# RS1xxxx register map
Vendor: Silicon Lab Inc.; Series: ARMCM4; File version: 1.2
CPU: CM4 r1p0, little endian, MPU, FPU, 6 interrupt priority bits
Registers are 32-bit, read-write, reset 0x0 unless marked. A register's access mark holds for its fields unless they carry their own. Offsets are from the block's base; [hi:lo] are bit positions; {n}, {i} and the like mark numbered series; 'fields as' and 'values as' point back to an identical list.

## QSPI_2 (part 2 of 2) — The queued serial peripheral interface module provides a serial peripheral interface with queued transfer capability
Base 0x12040000
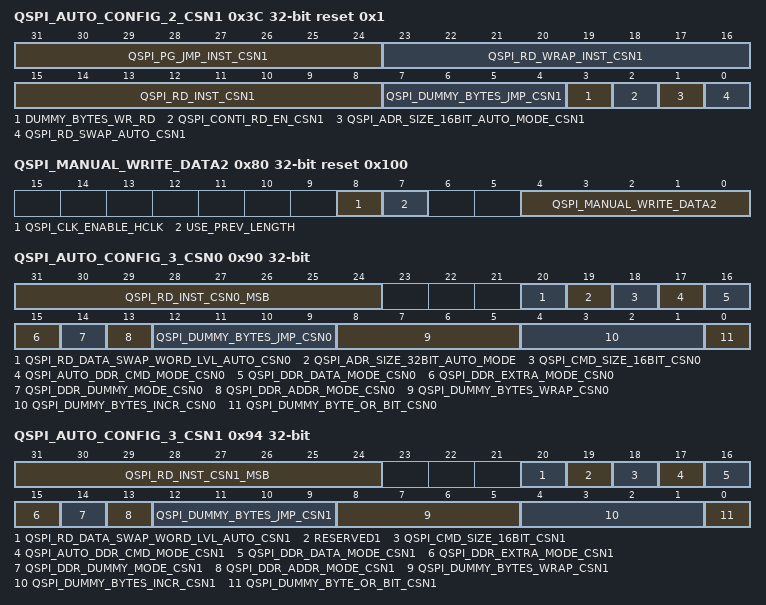
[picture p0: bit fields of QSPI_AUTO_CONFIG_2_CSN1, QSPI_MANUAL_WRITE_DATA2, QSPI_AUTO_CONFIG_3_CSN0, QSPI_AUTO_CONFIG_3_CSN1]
0x3C QSPI_AUTO_CONFIG_2_CSN1 reset 0x1 — QSPI Auto Controller Configuration 2 CSN1 Register
  [31:24] QSPI_PG_JMP_INST_CSN1 — Read instruction to be used, when Page jump is to be used.
  [23:16] QSPI_RD_WRAP_INST_CSN1 — Read instruction to be used for the selected SPI modes and when wrap is not needed or supported
  [15:8] QSPI_RD_INST_CSN1 — Read instruction to be used for the selected SPI modes and when wrap is not needed or supported
  [7:4] QSPI_DUMMY_BYTES_JMP_CSN1 — Dummy cycles to be selected in case of JUMP
  [3] DUMMY_BYTES_WR_RD — Dummy bytes to the model to be read or to be write.
    0=Disable (Dummy bytes will be read); 1=Enable (Dummy bytes to be write)
  [2] QSPI_CONTI_RD_EN_CSN1 — Continuous read enable bit.
    0=Disable (Continuous read disabled); 1=Enable (Continuous read enabled.)
  [1] QSPI_ADR_SIZE_16BIT_AUTO_MODE_CSN1 — Bit address sent to model
    0=Disable (24 Bit address is sent to model.); 1=Enable (16 Bit address is sent to model)
  [0] QSPI_RD_SWAP_AUTO_CSN1 — Swap the read data from the flash in byte order for chip select1 csn1 in auto mode.
    0=Swap_Disable (Swap is disabled.); 1=Swap_Enable (Swap is enabled)
0x80 QSPI_MANUAL_WRITE_DATA2 reset 0x100 (reset mask 0xFF)
  [8] QSPI_CLK_ENABLE_HCLK — Static clock enable for qspi hclock
  [7] USE_PREV_LENGTH — Use previous length.
    0=Disable (No action); 1=Enable (Uses previously programmed length in [4:0] of this register for next writes)
  [4:0] QSPI_MANUAL_WRITE_DATA2 — Number of bits to be written in write mode
0x90 QSPI_AUTO_CONFIG_3_CSN0 — QSPI Auto Controller Configuration 3 CSN0 Register
  [31:24] QSPI_RD_INST_CSN0_MSB — Read instruction MS byte to be used the selected SPI modes and when wrap is not needed or supported.
  [20] QSPI_RD_DATA_SWAP_WORD_LVL_AUTO_CSN0 — Rd data swap at word level in auto mode for csn0. It is valid for octa mode.
  [19] QSPI_ADR_SIZE_32BIT_AUTO_MODE — 32 bit addressing support enable.
    0=Disable (24/16 Bit address is sent to model.); 1=Enable (32 Bit address is sent to model.)
  [18] QSPI_CMD_SIZE_16BIT_CSN0 — Enable for 16 read cmd size for csn0.
    0=Disable (8 bit read command); 1=Enable (16 bit read command)
  [17] QSPI_AUTO_DDR_CMD_MODE_CSN0 — DDR data mode.In the SPI operation (cmd, addr, extra, dummy, data)
    0=Disable (Command byte is driven in SDR fashion.); 1=Enable (Command byte is driven in DDR fashion.)
  [16] QSPI_DDR_DATA_MODE_CSN0 — DDR data mode.In the SPI operation (cmd, addr, extra, dummy, data)
    0=Disable (Data are sampled in SDR fashion); 1=Enable (Data are sampled in DDR fashion)
  [15] QSPI_DDR_EXTRA_MODE_CSN0 — DDR extra byte mode.In the SPI operation (cmd, addr, extra, dummy, data)
    0=Disable (Dummy bytes are driven in SDR fashion.); 1=Enable (Dummy bytes are driven in DDR fashion.)
  [14] QSPI_DDR_DUMMY_MODE_CSN0 — DDR dummy byte mode.In the SPI operation (cmd, addr, extra, dummy, data)
    0=Disable (Extra byte is driven in SDR fashion.); 1=Enable (Extra byte is driven in DDR fashion.)
  [13] QSPI_DDR_ADDR_MODE_CSN0 — DDR Address mode. In the SPI operation (cmd, addr, extra, dummy, data)
    0=Disable (Address bytes are driven in SDR fashion); 1=Enable (Address bytes are driven in DDR fashion)
  [12:9] QSPI_DUMMY_BYTES_JMP_CSN0 — Dummy cycles to be selected in case of JUMP. It contains MS nibble of byte.
  [8:5] QSPI_DUMMY_BYTES_WRAP_CSN0 — Specifies the number of dummy bytes for the selected SPI mode in case of wrap instruction. It contains MS nibble for byte.
  [4:1] QSPI_DUMMY_BYTES_INCR_CSN0 — Specifies the number of dummy bytes for the selected SPI mode. It contains MS nibble for byte.
  [0] QSPI_DUMMY_BYTE_OR_BIT_CSN0 — Indicates all above mention values are dummy bytes or bits in auto mode.
    0=Disable (dummy bytes mode); 1=Enable (dummy bits mode)
0x94 QSPI_AUTO_CONFIG_3_CSN1 — QSPI Auto Controller Configuration 3 CSN1 Register
  [31:24] QSPI_RD_INST_CSN1_MSB — Read instruction MS byte to be used the selected SPI modes and when wrap is not needed or supported.
  [20] QSPI_RD_DATA_SWAP_WORD_LVL_AUTO_CSN1 — Rd data swap at word level in auto mode for csn1. It is valid for octa mode.
  [19] RESERVED1 — Reseerved1
  [18] QSPI_CMD_SIZE_16BIT_CSN1 — Enable for 16 read cmd size for csn1.
    values as QSPI_AUTO_CONFIG_3_CSN0.QSPI_CMD_SIZE_16BIT_CSN0
  [17] QSPI_AUTO_DDR_CMD_MODE_CSN1 — DDR data mode for csn1.In the SPI operation (cmd, addr, extra, dummy, data)
    0=Disable (Command byte is driven in SDR fashion); 2=Enable (Command byte is driven in DDR fashion)
  [16] QSPI_DDR_DATA_MODE_CSN1 — DDR data mode for csn1.In the SPI operation (cmd, addr, extra, dummy, data)
    0=Disable (Data are sampled in SDR fashion); 3=Enable (Data are sampled in DDR fashion)
  [15] QSPI_DDR_EXTRA_MODE_CSN1 — DDR extra byte mode for csn1.In the SPI operation (cmd, addr, extra, dummy, data)
    0=Disable (Dummy bytes are driven in SDR fashion); 4=Enable (Dummy bytes are driven in DDR fashion)
  [14] QSPI_DDR_DUMMY_MODE_CSN1 — DDR dummy byte mode for csn1.In the SPI operation (cmd, addr, extra, dummy, data)
    0=Disable (Extra byte is driven in SDR fashion); 5=Enable (Extra byte is driven in DDR fashion)
  [13] QSPI_DDR_ADDR_MODE_CSN1 — DDR address mode for csn1.In the SPI operation (cmd, addr, extra, dummy, data)
    0=Disable (Address bytes are driven in SDR fashion); 6=Enable (Address bytes are driven in DDR fashion)
  [12:9] QSPI_DUMMY_BYTES_JMP_CSN1 — Dummy cycles to be selected in case of JUMP. It contains MS nibble of byte.
  [8:5] QSPI_DUMMY_BYTES_WRAP_CSN1 — Specifies the number of dummy bytes for the selected SPI mode in case of wrap instruction. It contains MS nibble for byte.
  [4:1] QSPI_DUMMY_BYTES_INCR_CSN1 — Specifies the number of dummy bytes for the selected SPI mode. It contains MS nibble for byte.
  [0] QSPI_DUMMY_BYTE_OR_BIT_CSN1 — Indicates all above mention values are dummy bytes or bits in auto mode.
0xA0 QSPI_AUTO_BASE_ADDR_CSN0 — QSPI Controller auto Base address configuration CSN0 Register
  [31:0] QSPI_AUTO_BASE_ADDR_CSN0 — Holds the 32 bit base address for select chip select0 in programmable auto csn mode.It is valid only programmable auto csn mode is enabled.
0xA4 QSPI_AUTO_BASE_ADDR_CSN1 — QSPI Controller auto Base address configuration CSN1 Register
  [31:0] QSPI_AUTO_BASE_ADDR_CSN1 — Holds the 32 bit base address for select chip select1 in programmable auto csn mode.It is valid only programmable auto csn mode is enabled.
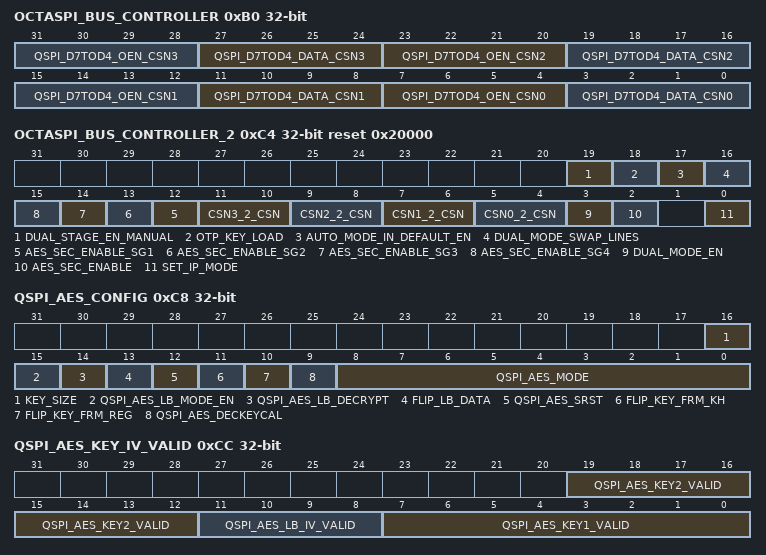
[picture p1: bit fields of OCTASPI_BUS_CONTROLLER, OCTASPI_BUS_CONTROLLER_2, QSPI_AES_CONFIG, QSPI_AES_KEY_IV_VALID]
0xB0 OCTASPI_BUS_CONTROLLER
  [8n+7:8n+4] QSPI_D7TOD4_OEN_CSN{n} (n=0..3) — Direction Control for SPI_IO 7,6,5 and 4 in case of quad/dual/single mode for chip select{n} (cs_n{n}). It is used both in Auto and Manual Mode.
  [27:24] QSPI_D7TOD4_DATA_CSN3 — Value of SPI_IO7,6,5 and 4 in case of quad/dual/single mode for chip select3 (cs_n3). It is used both in Auto and Manual Mode.
  [19:16] QSPI_D7TOD4_DATA_CSN2 — Value of SPI_IO7,6,5 and 4 in case of quad/dual/single mode for chip select2 (cs_n2). It is used both in Auto and Manual Mode.
  [11:8] QSPI_D7TOD4_DATA_CSN1 — Value of SPI_IO7,6,5 and 4 in case of quad/dual/single mode for chip select1 (cs_n1). It is used both in Auto and Manual Mode.
  [3:0] QSPI_D7TOD4_DATA_CSN0 — Value of SPI_IO7,6,5 and 4 in case of quad/dual/single mode for chip select1 (cs_n0). It is used both in Auto and Manual Mode.
0xB4 QSPI_AUTO_BASE_ADDR_UNMASK_CSN0 reset 0xFFFFFFFF — QSPI in Auto Base address mode for unmasking CSN0 Register
  [31:0] QSPI_AUTO_BASE_ADDR_UNMASK_CSN0 — Holds the 32 bit base address unmask value for select chip select0 in programmable auto csn mode. It is valid only programmable auto csn mode is enabled.
0xB8 QSPI_AUTO_BASE_ADDR_UNMASK_CSN1 reset 0xFFFFFFFF — QSPI in Auto Base address mode for unmasking CSN1 Register
  [31:0] QSPI_AUTO_BASE_ADDR_UNMASK_CSN1 — Holds the 32 bit base address unmask value for select chip select1 in programmable auto csn mode. It is valid only programmable auto csn mode is enabled.
0xC4 OCTASPI_BUS_CONTROLLER_2 reset 0x20000 — QSPI Controller2 in OCTA SPI Mode.
  [19] DUAL_STAGE_EN_MANUAL — Dual stage en for dual flash mode. It is valid only if dual_mode_en is set to high. This bit be one, while sending command, address, dummy bytes, and etc. It sends same command & address to both flashes. It should be zero while reading or writing data into flash in dual quad flash mode.
  [18] OTP_KEY_LOAD — Enable to load key from OTP/KH
  [17] AUTO_MODE_IN_DEFAULT_EN — Qspi works in auto mode if set this is bit by default.
  [16] DUAL_MODE_SWAP_LINES — This bit controls the 8 lines of qspi with 4 bit swap manner. If this is set, upper 4 lines are swapped with lower 4 lines.
  [n+11] AES_SEC_ENABLE_SG{n} (n=1..4) — This bit enables the AES security enable or not for segment {n}
  [11:10] CSN3_2_CSN — Map csn3 to the programmed csn. It is valid for both manual and auto modes
    0=CSN3_TO_CSN0 (Map csn3 to csn0. Reads on csn3 will have data from csn0 also.); 7=CSN3_TO_CSN1 (Map csn3 to csn1. Reads on csn3 will have data from csn0 also); 8=CSN3_TO_CSN2 (Map csn3 to csn2. Reads on csn3 will have data from csn0 also.); 3=NOT_VALID
  [9:8] CSN2_2_CSN — Map csn2 to the programmed csn. It is valid for both manual and auto modes
    0=CSN2_TO_CSN1 (Map csn2 to csn1. Reads on csn2 will have data from csn0 also); 9=CSN2_TO_CSN1 (Map csn2 to csn1. Reads on csn2 will have data from csn1 also); 10=NOT_VALID; 3=CSN2_TO_CSN3 (Map csn2 to csn3. Reads on csn2 will have data from csn3 also.)
  [7:6] CSN1_2_CSN — Map csn1 to the programmed csn. It is valid for both manual and auto modes
    0=CSN1_TO_CSN0 (Map csn1 to csn0. Reads on csn1 will have data from csn1 also); 11=NOT_VALID; 12=CSN1_TO_CSN2 (Map csn1 to csn2. Reads on csn1 will have data from csn2 also); 3=CSN1_TO_CSN3 (Map csn1 to csn3. Reads on csn1 will have data from csn3 also)
  [5:4] CSN0_2_CSN — Map csn0 to the programmed csn. It is valid for both manual and auto modes
    0=NOT_VALID; 13=CSN0_TO_CSN1 (Map csn0 to csn1. Reads on csn0 will have data from csn1 also); 14=CSN0_TO_CSN2 (Map csn0 to csn2. Reads on csn0 will have data from csn2 also); 3=CSN0_TO_CSN3 (Map csn0 to csn3. Reads on csn0 will have data from csn3 also)
  [3] DUAL_MODE_EN — Dual flash mode enable control. If two csns are cmnnected with the same kind of flash, QSPI can read data (4bit data each flash) from both the flashes at the same point of time (Not in TDM fashion). If set, both the flashes are accessed at the same point time, otherwise normal operation.
  [2] AES_SEC_ENABLE — This bit enables the AES security enable or not
  [0] SET_IP_MODE — This bit enables the qspi interface pins into HiZ mode
0xC8 QSPI_AES_CONFIG — QSPI Controller AES Mode, Key Size and Context switching
  [16] KEY_SIZE — QSPI key size
    0=Disable (124 bit key); 1=Enable (256 bit key)
  [15] QSPI_AES_LB_MODE_EN — QSPI AES LB mode (Standalone mode ) enable.
    0=Disable (Inline mode); 1=Enable (Standalone mode)
  [14] QSPI_AES_LB_DECRYPT — QSPI standalone mode
    0=Disable (Enables encryption mode in standalone mode); 1=Enables decryption mode in standalone mode
  [13] FLIP_LB_DATA — writing 1 to this Flips the 32-bit endian for data in standalone mode
  [12] QSPI_AES_SRST wo — Synchronous soft reset for AES Module. Write only bit. Reading this bit gives alway 0
  [11] FLIP_KEY_FRM_KH — writing 1 to this Flips the 32-bit endian key taken from kh
  [10] FLIP_KEY_FRM_REG — writing 1 to this Flips the 32-bit endian key taken from kh
  [9] QSPI_AES_DECKEYCAL — Enables pre-calculation of KEY before decryption operation. Set 1 fot XTS and 0 for CTR In encryption operations, it is 0. 1 not supported.
    0=Disable (use the input key for decryption operations.); 1=Enable (the pre-calculation of the key (K’=KeyExp(K)) is done before starting any data decryption operation)
  [8:0] QSPI_AES_MODE — AES mode of decryption CTR/XTS 0x80 - XTS 0x04 - CTR others not supported
0xCC QSPI_AES_KEY_IV_VALID — QSPI Controller AES write Enables for Keys and IVs
  [19:12] QSPI_AES_KEY2_VALID — Write enables for AES KEY 2. Denotes which bytes of key2 is valid
  [11:8] QSPI_AES_LB_IV_VALID — Write enables for AES IV1 in standalone mode. Denotes which bytes of IV1 is valid.
  [7:0] QSPI_AES_KEY1_VALID — Write enables for AES KEY 1. Denotes which bytes of key1 is valid
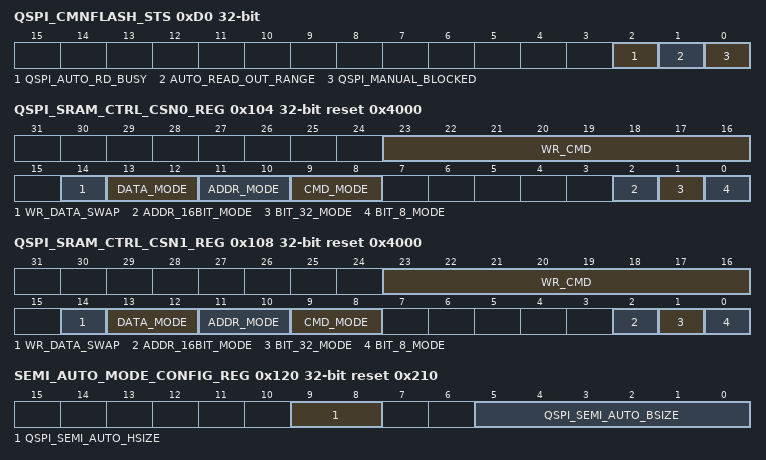
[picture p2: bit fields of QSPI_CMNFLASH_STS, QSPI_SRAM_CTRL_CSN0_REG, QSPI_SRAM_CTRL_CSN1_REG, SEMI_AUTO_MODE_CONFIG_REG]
0xD0 QSPI_CMNFLASH_STS ro — QSPI Status in Common flash modes
  [2] QSPI_AUTO_RD_BUSY — Auto read transactions
    0=Disable (No Auto read transactions); 1=Enable (Auto read transactions in progress.)
  [1] AUTO_READ_OUT_RANGE — Auto read transaction of address
    0=Disable (Auto read transaction is in Address range); 1=Enable (Auto read transaction is out of M4 Address range)
  [0] QSPI_MANUAL_BLOCKED — QSPI manual transactions
    0=Disable (No manual transactions); 1=Enable (Manual read/write transaction initiated is blocked.)
0xD4 QSPI_AES_LB_DATA_0_3 — QSPI AES in LB (Standalone mode ) for [31:0]
  [31:0] QSPI_AES_LB_DIN_0_3 wo — write 3-0 bytes of aes standalone mode input data as 0 referred as lsb in the data in
  [31:0] QSPI_AES_LB_DOUT_0_3 ro — read 3-0 bytes of aes standalone mode output data as 0 referred as lsb in the data out Inline mode input data is loop back as out data
0xD8 QSPI_AES_LB_DATA_4_7 rw-once — QSPI AES in LB (Standalone mode ) for [63:32]
  [31:0] QSPI_AES_LB_DIN_4_7 wo — write 7-4 bytes of aes standalone mode input data as 0 referred as lsb in the data in
  [31:0] QSPI_AES_LB_DOUT_4_7 ro — read 7-4 bytes of aes standalone mode output data as 0 referred as lsb in the data out Inline mode input data is loop back as out data
0xDC QSPI_AES_LB_DATA_8_B rw-once — QSPI AES in LB (Standalone mode ) for [95:64]
  [31:0] QSPI_AES_LB_DIN_8_B wo — write 11-8 bytes of aes standalone mode input data as 0 referred as lsb in the data in
  [31:0] QSPI_AES_LB_DOUT_8_B ro — read 11-8 bytes of aes standalone mode output data as 0 referred as lsb in the data out Inline mode input data is loop back as out data
0xE0 QSPI_AES_LB_DATA_C_F rw-once — QSPI AES in LB (Standalone mode ) for [127:96]
  [31:0] QSPI_AES_LB_DIN_C_F wo — write 15-12 bytes of aes standalone mode input data as 0 referred as lsb in the data in
  [31:0] QSPI_AES_LB_DOUT_C_F ro — read 15-12 bytes of aes standalone mode output data as 0 referred as lsb in the data out Inline mode input data is loop back as out data
0xE4 QSPI_AES_SEC_SEG_LS_ADDR_1 — QSPI Controller AES lower boundary address of 1st segment
  [31:0] QSPI_AES_SEC_SEG_LS_ADDR_1 — This register specifies the lower boundary address of 1st segment
0xE8 QSPI_AES_SEC_SEG_MS_ADDR_1 — QSPI Controller AES upper boundary address of 1st segment
  [31:0] QSPI_AES_SEC_SEG_MS_ADDR_1 — This register specifies the upper boundary address of 1st segment
0xEC QSPI_AES_SEC_SEG_LS_ADDR_2 — QSPI Controller AES lower boundary address of 2nd segment
  [31:0] QSPI_AES_SEC_SEG_LS_ADDR_2 — This register specifies the lower boundary address of 2nd segment
0xF0 QSPI_AES_SEC_SEG_MS_ADDR_2 — QSPI Controller AES upper boundary address of 2nd segment
  [31:0] QSPI_AES_SEC_SEG_MS_ADDR_2 — This register specifies the upper boundary address of 2nd segment
0xF4 QSPI_AES_SEC_SEG_LS_ADDR_3 — QSPI Controller AES lower boundary address of 3rd segment
  [31:0] QSPI_AES_SEC_SEG_LS_ADDR_3 — This register specifies the lower boundary address of 3rd segment
0xF8 QSPI_AES_SEC_SEG_MS_ADDR_3 — QSPI Controller AES upper boundary address of 3rd segment
  [31:0] QSPI_AES_SEC_SEG_MS_ADDR_3 — This register specifies the upper boundary address of 3rd segment
0xFC QSPI_AES_SEC_SEG_LS_ADDR_4 — QSPI Controller AES lower boundary address of 4th segment
  [31:0] QSPI_AES_SEC_SEG_LS_ADDR_4 — This register specifies the lower boundary address of 4th segment
0x100 QSPI_AES_SEC_SEG_MS_ADDR_4 — QSPI Controller AES upper boundary address of 4th segment
  [31:0] QSPI_AES_SEC_SEG_MS_ADDR_4 — This register specifies the upper boundary address of 4th segment
0x104 QSPI_SRAM_CTRL_CSN0_REG reset 0x4000 — SRAM CTRL register of the QSPI Controller CSN0 register
  [23:16] WR_CMD — Command to be used for writing.
  [14] WR_DATA_SWAP — writing data swap
    0=Disable (WR DATA is not swapped); 1=Enable (WR DATA is swapped)
  [13:12] DATA_MODE — writing data mode
    0=Single SPI; 15=Dual SPI; 16=Quad SPI; 3=OCTA SPI
  [11:10] ADDR_MODE — writing address mode
    0=Single SPI; 17=Dual SPI; 18=Quad SPI; 3=OCTA SPI
  [9:8] CMD_MODE — writing cmd mode
    0=Single SPI; 19=Dual SPI; 20=Quad SPI; 3=OCTA SPI
  [2] ADDR_16BIT_MODE — Send only lower 16bits of Address enable.
    0=Disable (24 address bit flash is connected.); 21=Enable (16 address bit flash is connected.)
  [1] BIT_32_MODE — Flash 32 byte boundary mode.
    0=Disable (Flash is not with 32 byte boundary.); 22=Enable (Flash is with 32 byte boundary.)
  [0] BIT_8_MODE — Flash 8bit (1 byte) boundary mode.
    0=Disable (Flash is not with 8bit (1 byte) boundary.); 23=Enable (Flash is with 8bit (1 byte) boundary.)
0x108 QSPI_SRAM_CTRL_CSN1_REG reset 0x4000 — SRAM CTRL register of the QSPI Controller CSN1 register
  fields as QSPI_SRAM_CTRL_CSN0_REG
0x11C SEMI_AUTO_MODE_ADDR_REG — QSPI Controller in SEMI AUTO mode for address
  [31:0] SEMI_AUTO_MODE_ADDR — Byte address to read the data from flash in semi auto mode. It is valid only semi auto mode enable bit is asserted.
0x120 SEMI_AUTO_MODE_CONFIG_REG reset 0x210 — QSPI Controller in SEMI AUTO mode for Configuration
  [9:8] QSPI_SEMI_AUTO_HSIZE — Indicates number of bytes valid in each transaction.24bytes mode is not supported because this hsize to be similar to ahb ahb hsize signal. It is valid only semi auto mode enable bit is asserted.
    0=1_BYTE (1 byte valid); 1=2_BYTES (2 bytes valid); 2=4_BYTES (4 bytes valid)
  [5:0] QSPI_SEMI_AUTO_BSIZE — This is burst size to read data from flash in semi auto mode. To get burst size in bytes, consider qspi_semi_auto_hsize also. qspi_semi_auto_bsize is non-zero value. 0x00 is not supported and invalid.
    4=B_SIZE (qspi_semi_auto_bsize); 2=H_SIZE (qspi_semi_auto_hsize)
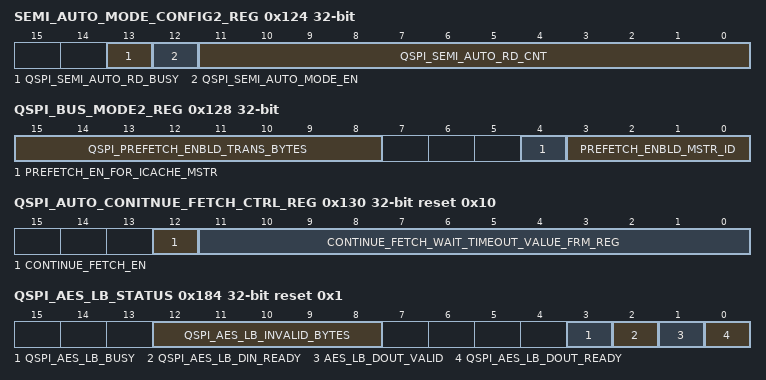
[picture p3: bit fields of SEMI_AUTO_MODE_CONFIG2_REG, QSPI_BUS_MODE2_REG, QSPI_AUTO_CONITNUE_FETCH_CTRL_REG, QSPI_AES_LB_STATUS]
0x124 SEMI_AUTO_MODE_CONFIG2_REG — QSPI Controller in SEMI AUTO mode for Configuration 2
  [13] QSPI_SEMI_AUTO_RD_BUSY ro — Indicates status of semi auto mode read status. If it is high, semi auto mode read operation is progressing. It is It is valid only semi auto mode enable bit is asserted.
  [12] QSPI_SEMI_AUTO_MODE_EN — Enable for semi auto mode read operation. Make sure manual mode read/write operation is completed before asserting this bit. Either manual mode or semi auto mode will work at a time. Don’t start any manual mode operation when this bit is asserted. Qspi_auto_mode and semi_auto_mode share qspi bus bandwidth and work simultaneously.
  [11:0] QSPI_SEMI_AUTO_RD_CNT — Total number of bytes to be read flash continuously from the address given by SEMI_AUTO_MODE_ADDR_REG. After reading complete data according to this count, qspi_semi_auto_rd_busy is de-asserted.
0x128 QSPI_BUS_MODE2_REG — QSPI Controller Bus in mode2.
  [15:8] QSPI_PREFETCH_ENBLD_TRANS_BYTES — Programmable prefetch enabled AHB master transfer bytes. Assume this is used for icache and dma ahb master access in auto mode.
  [4] PREFETCH_EN_FOR_ICACHE_MSTR — Prefetch enable for icache AHB master.
  [3:0] PREFETCH_ENBLD_MSTR_ID — Holds the programmable prefetch enabled AHB master ID. This is commonly used for enabling prefetch for icache master.
0x12C QSPI_AES_SEC_KEY_FRM_KH_REG reset 0x12 — QSPI Controller AES SEC KEY FRM_KH mode.
  [4:1] SEC_KEY_READING_INTERVAL — Security key reading interval KH key reading will happened at this rate, which is soc clock divided by this value. default reading rate is soc clock divided by 10.
  [0] START_LOADING_SEC_KEY_FRM_KH wo — Start Security key loading from KH. It self-clear bit. After setting the key loading bit, wait for de-assertion of this bit. Hardware resets this bit after key loading done.
  [0] LOADING_SEC_KEY_FRM_KH ro — Indicates security key loading status from KH
0x130 QSPI_AUTO_CONITNUE_FETCH_CTRL_REG reset 0x10 — QSPI Controller in Auto Continue Fetch mode.
  [12] CONTINUE_FETCH_EN — Continue fetch feature enable. If this mode is enabled & consecutive address is issued, It will continue reading of data in auto mode without de-asserting CSN. It saves command, address and dummy cycles phases. It has timeout option also. If consecutive address is given in the programmable specified time or non consecutive address is given, it deassert the CSN. It is valid only for auto mode. Disable this bit before any manual mode transactions. It is taken care automatically by qspi controller in hardware controlled auto mode. If continuous mode is enable, clock ratio between qspi clock and soc clock should 2:1, 1:1, 1:2, 1:3, .. 1:x.
  [11:0] CONTINUE_FETCH_WAIT_TIMEOUT_VALUE_FRM_REG — Maximum Continue fetch wait time between two qspi auto reads. After this time out, qspi auto controller will deassert the CSN.
0x134 QSPI_AES_KEY1_0_3 — QSPI Controller AES KEY1 from 0 to 3 bytes
  [31:0] QSPI_AES_KEY1_0_3 — To hold first 3-0 bytes of aes key1 as 0 referred as lsb in the key
0x138 QSPI_AES_KEY1_4_7 — QSPI Controller AES KEY1 from 4 to 7 bytes
  [31:0] QSPI_AES_KEY1_4_7 — To hold first 7-4 bytes of aes key1 as 0 referred as lsb
0x13C QSPI_AES_KEY1_8_B — QSPI Controller AES KEY1 from 8 to B bytes
  [31:0] QSPI_AES_KEY1_8_B — To hold first 11-8 bytes of aes key1 as 0 referred as lsb
0x140 QSPI_AES_KEY1_C_F — QSPI Controller AES KEY1 from C to F bytes
  [31:0] QSPI_AES_KEY1_C_F — To hold first 11-8 bytes of aes key1 as 0 referred as lsb
0x144 QSPI_AES_KEY1_10_13 — QSPI Controller AES KEY1 from 10 to 13 bytes
  [31:0] QSPI_AES_KEY1_10_13 — To hold first 19-16 bytes of aes key1 as 0 referred as lsb in the key
0x148 QSPI_AES_KEY1_14_17 — QSPI Controller AES KEY1 from 14 to 17 bytes
  [31:0] QSPI_AES_KEY1_14_17 — To hold first 23-20 bytes of aes key1 as 0 referred as lsb
0x14C QSPI_AES_KEY1_18_1B — QSPI Controller AES KEY1 from 18 to 1B bytes
  [31:0] QSPI_AES_KEY1_18_1B — To hold first 27-24 bytes of aes key1 as 0 referred as lsb
0x150 QSPI_AES_KEY1_1C_1F — QSPI Controller AES KEY1 from 1C to 1F bytes
  [31:0] QSPI_AES_KEY1_1C_1F — To hold first 31-28 bytes of aes key1 as 0 referred as lsb
0x154 QSPI_AES_KEY2_0_3 — QSPI Controller AES KEY2 from 0 to 3 bytes
  [31:0] QSPI_AES_KEY2_0_3 — To hold first 3-0 bytes of aes key2 as 0 referred as lsb in the key
0x158 QSPI_AES_KEY2_4_7 — QSPI Controller AES KEY2 from 4 to 7 bytes
  [31:0] QSPI_AES_KEY2_4_7 — To hold first 7-4 bytes of aes key2 as 0 referred as lsb
0x15C QSPI_AES_KEY2_8_B — QSPI Controller AES KEY2 from 8 to B bytes
  [31:0] QSPI_AES_KEY2_8_B — To hold first 11-8 bytes of aes key2 as 0 referred as lsb
0x160 QSPI_AES_KEY2_C_F — QSPI Controller AES KEY2 from C to F bytes
  [31:0] QSPI_AES_KEY2_C_F — To hold first 15-12 bytes of aes key2 as 0 referred as lsb
0x164 QSPI_AES_KEY2_10_13 — QSPI Controller AES KEY2 from 10 to 13 bytes
  [31:0] QSPI_AES_KEY2_10_13 — To hold first 19-16 bytes of aes KEY2 as 0 referred as lsb in the key
0x168 QSPI_AES_KEY2_14_17 — QSPI Controller AES KEY2 from 14 to 17 bytes
  [31:0] QSPI_AES_KEY2_14_17 — To hold first 23-20 bytes of aes KEY2 as 0 referred as lsb
0x16C QSPI_AES_KEY2_18_1B — QSPI Controller AES KEY2 from 18 to 1B bytes
  [31:0] QSPI_AES_KEY2_18_1B — To hold first 27-24 bytes of aes KEY2 as 0 referred as lsb
0x170 QSPI_AES_KEY2_1C_1F — QSPI Controller AES KEY2 from 1C to 1F bytes
  [31:0] QSPI_AES_KEY2_1C_1F — To hold first 31-28 bytes of aes KEY2 as 0 referred as lsb
0x174 QSPI_AES_IV1_0_3 — QSPI Controller AES IV1 from 0 to 3 bytes in LB mode
  [31:0] QSPI_AES_LB_IV — To hold first 3-0 bytes of QSPI AES IV1 as 0 referred as lsb in the IV in stadalone mode
0x178 QSPI_AES_IV1_4_7 — QSPI Controller AES IV1 from 4 to 7 bytes in LB mode
  [31:0] QSPI_AES_LB_IV — To hold first 7-4 bytes of QSPI AES IV1 as 0 referred as lsb in the IV in stadalone mode
0x17C QSPI_AES_IV1_8_B — QSPI Controller AES IV1 from 8 to B bytes in LB mode
  [31:0] QSPI_AES_LB_IV — To hold first B-8 bytes of QSPI AES IV1 as 0 referred as lsb in the IV in stadalone mode
0x180 QSPI_AES_IV1_C_F — QSPI Controller AES IV1 from 8 to B bytes in LB mode
  [31:0] QSPI_AES_LB_IV — To hold first F-C bytes of QSPI AES IV1 as F referred as msb in the IV in stadalone mode
0x184 QSPI_AES_LB_STATUS rw-once reset 0x1 — QSPI Controller AES IV1 from 8 to B bytes in LB mode
  [12:8] QSPI_AES_LB_INVALID_BYTES rw — Denotes number of invalid bytes in data input in loop back mode.
  [3] QSPI_AES_LB_BUSY ro — Denotes busy status of QSPI AES in loop back mode
  [2] QSPI_AES_LB_DIN_READY ro — Denotes ready status of QSPI AES in loop back mode
  [1] AES_LB_DOUT_VALID ro — Denotes validity of out data of QSPI AES in loop back mode
  [0] QSPI_AES_LB_DOUT_READY rw — Denotes the firmware is ready to read to output data.
